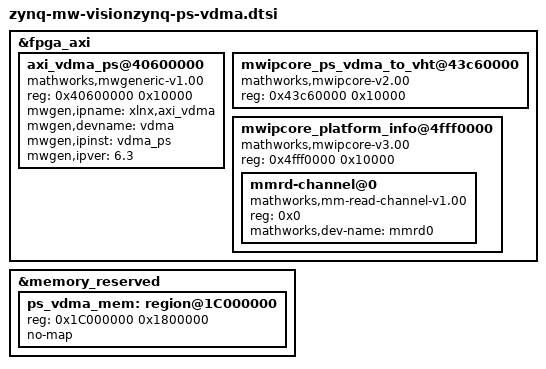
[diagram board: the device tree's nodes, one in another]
&fpga_axi {	
	axi_vdma_ps@40600000 {
		compatible = "mathworks,mwgeneric-v1.00";
		reg = <0x40600000 0x10000>;
		mwgen,ipname = "xlnx,axi_vdma";
		mwgen,devname = "vdma";
		mwgen,ipinst = "vdma_ps";
		mwgen,ipver = "6.3";
	};
	
	mwipcore_ps_vdma_to_vht@43c60000 {
		compatible = "mathworks,mwipcore-v2.00";
		reg = <0x43c60000 0x10000>;
	};
	
	mwipcore_platform_info@4fff0000 {
		compatible = "mathworks,mwipcore-v3.00";
		reg = <0x4fff0000 0x10000>;
		#address-cells = <1>;
		#size-cells = <0>;

		mmrd-channel@0 {
			reg = <0x0>;
			compatible = "mathworks,mm-read-channel-v1.00";
			mathworks,dev-name = "mmrd0";
		};
	};
};

&memory_reserved {
	ps_vdma_mem: region@1C000000 {
		reg = <0x1C000000 0x1800000>;
		no-map;
	};
};


